# VPAC0_CP_INTD_CFG_INTD_CFG register map
Vendor: Texas Instruments
Peripheral module from a debugger description file (folder J7ES).
Registers are 32-bit, access not given, reset values left out (the file's numbers can be read two ways) unless marked. A register's access mark holds for its fields unless they carry their own. Offsets are as the file gives them; lines under a group give offsets from that group; [hi:lo] are bit positions; {n}, {i} and the like mark numbered series; 'fields as' and 'values as' point back to an identical list; <NAME> marks a mode.

## VPAC0_CP_INTD_CFG_INTD_CFG (part 1 of 2)
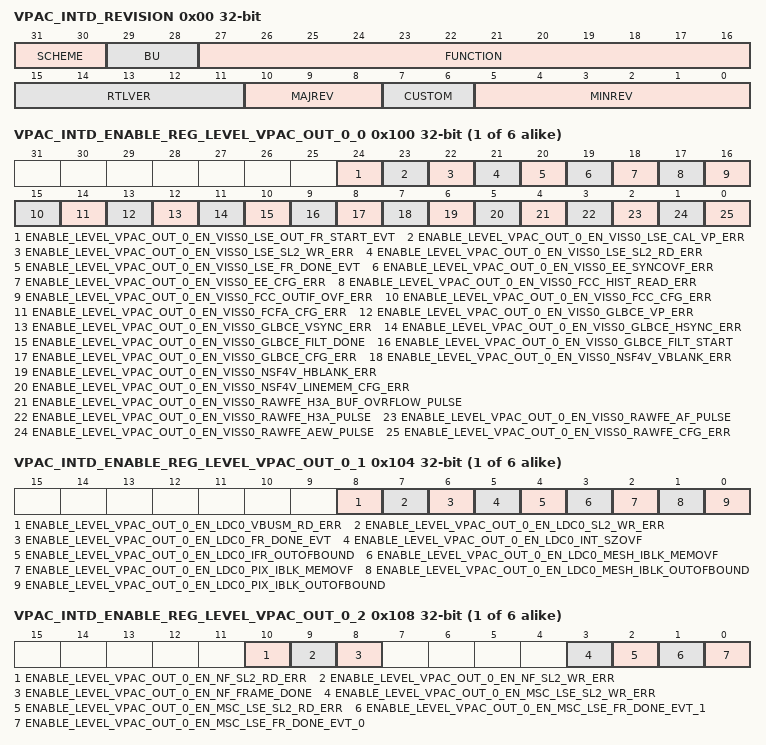
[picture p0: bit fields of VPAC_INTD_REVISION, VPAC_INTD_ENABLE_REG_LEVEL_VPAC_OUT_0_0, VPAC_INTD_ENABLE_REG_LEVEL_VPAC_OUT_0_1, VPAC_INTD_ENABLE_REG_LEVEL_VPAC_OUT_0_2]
0x00 VPAC_INTD_REVISION ro — Register
  [31:30] SCHEME
  [29:28] BU
  [27:16] FUNCTION — Module ID
  [15:11] RTLVER — RTL revisions
  [10:8] MAJREV — Major
  [7:6] CUSTOM
  [5:0] MINREV — Minor
0x10 VPAC_INTD_EOI_REG rw — End of Interrupt Register The EOI register is used to re-trigger the pulse interrupt signal to ensure that any nested interrupt events are serviced. The software interrupt handler must write to the EOI register at the end of the current interrupt processing routine, so that new events can re-trigger the pulse interrupt signal again. For level interrupt signals the EOI register is not functional and must not be used.
  [7:0] EOI_VECTOR — End of Interrupt Vector
0x14 VPAC_INTD_INTR_VECTOR_REG ro — Interrupt Vector Register
  [31:0] INTR_VECTOR
{0x100+0x20*i} VPAC_INTD_ENABLE_REG_LEVEL_VPAC_OUT_{i}_0 (i=0..5) — Enable Register {8i}
  [24] ENABLE_LEVEL_VPAC_OUT_{i}_EN_VISS0_LSE_OUT_FR_START_EVT — Enable Set for level_vpac_out_{i}_en_viss0_lse_out_fr_start_evt (access RW1S)
  [23] ENABLE_LEVEL_VPAC_OUT_{i}_EN_VISS0_LSE_CAL_VP_ERR — Enable Set for level_vpac_out_{i}_en_viss0_lse_cal_vp_err (access RW1S)
  [22] ENABLE_LEVEL_VPAC_OUT_{i}_EN_VISS0_LSE_SL2_WR_ERR — Enable Set for level_vpac_out_{i}_en_viss0_lse_sl2_wr_err (access RW1S)
  [21] ENABLE_LEVEL_VPAC_OUT_{i}_EN_VISS0_LSE_SL2_RD_ERR — Enable Set for level_vpac_out_{i}_en_viss0_lse_sl2_rd_err (access RW1S)
  [20] ENABLE_LEVEL_VPAC_OUT_{i}_EN_VISS0_LSE_FR_DONE_EVT — Enable Set for level_vpac_out_{i}_en_viss0_lse_fr_done_evt (access RW1S)
  [19] ENABLE_LEVEL_VPAC_OUT_{i}_EN_VISS0_EE_SYNCOVF_ERR — Enable Set for level_vpac_out_{i}_en_viss0_ee_syncovf_err (access RW1S)
  [18] ENABLE_LEVEL_VPAC_OUT_{i}_EN_VISS0_EE_CFG_ERR — Enable Set for level_vpac_out_{i}_en_viss0_ee_cfg_err (access RW1S)
  [17] ENABLE_LEVEL_VPAC_OUT_{i}_EN_VISS0_FCC_HIST_READ_ERR — Enable Set for level_vpac_out_{i}_en_viss0_fcc_hist_read_err (access RW1S)
  [16] ENABLE_LEVEL_VPAC_OUT_{i}_EN_VISS0_FCC_OUTIF_OVF_ERR — Enable Set for level_vpac_out_{i}_en_viss0_fcc_outif_ovf_err (access RW1S)
  [15] ENABLE_LEVEL_VPAC_OUT_{i}_EN_VISS0_FCC_CFG_ERR — Enable Set for level_vpac_out_{i}_en_viss0_fcc_cfg_err (access RW1S)
  [14] ENABLE_LEVEL_VPAC_OUT_{i}_EN_VISS0_FCFA_CFG_ERR — Enable Set for level_vpac_out_{i}_en_viss0_fcfa_cfg_err (access RW1S)
  [13] ENABLE_LEVEL_VPAC_OUT_{i}_EN_VISS0_GLBCE_VP_ERR — Enable Set for level_vpac_out_{i}_en_viss0_glbce_vp_err (access RW1S)
  [12] ENABLE_LEVEL_VPAC_OUT_{i}_EN_VISS0_GLBCE_VSYNC_ERR — Enable Set for level_vpac_out_{i}_en_viss0_glbce_vsync_err (access RW1S)
  [11] ENABLE_LEVEL_VPAC_OUT_{i}_EN_VISS0_GLBCE_HSYNC_ERR — Enable Set for level_vpac_out_{i}_en_viss0_glbce_hsync_err (access RW1S)
  [10] ENABLE_LEVEL_VPAC_OUT_{i}_EN_VISS0_GLBCE_FILT_DONE — Enable Set for level_vpac_out_{i}_en_viss0_glbce_filt_done (access RW1S)
  [9] ENABLE_LEVEL_VPAC_OUT_{i}_EN_VISS0_GLBCE_FILT_START — Enable Set for level_vpac_out_{i}_en_viss0_glbce_filt_start (access RW1S)
  [8] ENABLE_LEVEL_VPAC_OUT_{i}_EN_VISS0_GLBCE_CFG_ERR — Enable Set for level_vpac_out_{i}_en_viss0_glbce_cfg_err (access RW1S)
  [7] ENABLE_LEVEL_VPAC_OUT_{i}_EN_VISS0_NSF4V_VBLANK_ERR — Enable Set for level_vpac_out_{i}_en_viss0_nsf4v_vblank_err (access RW1S)
  [6] ENABLE_LEVEL_VPAC_OUT_{i}_EN_VISS0_NSF4V_HBLANK_ERR — Enable Set for level_vpac_out_{i}_en_viss0_nsf4v_hblank_err (access RW1S)
  [5] ENABLE_LEVEL_VPAC_OUT_{i}_EN_VISS0_NSF4V_LINEMEM_CFG_ERR — Enable Set for level_vpac_out_{i}_en_viss0_nsf4v_linemem_cfg_err (access RW1S)
  [4] ENABLE_LEVEL_VPAC_OUT_{i}_EN_VISS0_RAWFE_H3A_BUF_OVRFLOW_PULSE — Enable Set for level_vpac_out_{i}_en_viss0_rawfe_h3a_buf_ovrflow_pulse (access RW1S)
  [3] ENABLE_LEVEL_VPAC_OUT_{i}_EN_VISS0_RAWFE_H3A_PULSE — Enable Set for level_vpac_out_{i}_en_viss0_rawfe_h3a_pulse (access RW1S)
  [2] ENABLE_LEVEL_VPAC_OUT_{i}_EN_VISS0_RAWFE_AF_PULSE — Enable Set for level_vpac_out_{i}_en_viss0_rawfe_af_pulse (access RW1S)
  [1] ENABLE_LEVEL_VPAC_OUT_{i}_EN_VISS0_RAWFE_AEW_PULSE — Enable Set for level_vpac_out_{i}_en_viss0_rawfe_aew_pulse (access RW1S)
  [0] ENABLE_LEVEL_VPAC_OUT_{i}_EN_VISS0_RAWFE_CFG_ERR — Enable Set for level_vpac_out_{i}_en_viss0_rawfe_cfg_err (access RW1S)
{0x104+0x20*i} VPAC_INTD_ENABLE_REG_LEVEL_VPAC_OUT_{i}_1 (i=0..5) — Enable Register {8i+1}
  [8] ENABLE_LEVEL_VPAC_OUT_{i}_EN_LDC0_VBUSM_RD_ERR — Enable Set for level_vpac_out_{i}_en_ldc0_vbusm_rd_err (access RW1S)
  [7] ENABLE_LEVEL_VPAC_OUT_{i}_EN_LDC0_SL2_WR_ERR — Enable Set for level_vpac_out_{i}_en_ldc0_sl2_wr_err (access RW1S)
  [6] ENABLE_LEVEL_VPAC_OUT_{i}_EN_LDC0_FR_DONE_EVT — Enable Set for level_vpac_out_{i}_en_ldc0_fr_done_evt (access RW1S)
  [5] ENABLE_LEVEL_VPAC_OUT_{i}_EN_LDC0_INT_SZOVF — Enable Set for level_vpac_out_{i}_en_ldc0_int_szovf (access RW1S)
  [4] ENABLE_LEVEL_VPAC_OUT_{i}_EN_LDC0_IFR_OUTOFBOUND — Enable Set for level_vpac_out_{i}_en_ldc0_ifr_outofbound (access RW1S)
  [3] ENABLE_LEVEL_VPAC_OUT_{i}_EN_LDC0_MESH_IBLK_MEMOVF — Enable Set for level_vpac_out_{i}_en_ldc0_mesh_iblk_memovf (access RW1S)
  [2] ENABLE_LEVEL_VPAC_OUT_{i}_EN_LDC0_PIX_IBLK_MEMOVF — Enable Set for level_vpac_out_{i}_en_ldc0_pix_iblk_memovf (access RW1S)
  [1] ENABLE_LEVEL_VPAC_OUT_{i}_EN_LDC0_MESH_IBLK_OUTOFBOUND — Enable Set for level_vpac_out_{i}_en_ldc0_mesh_iblk_outofbound (access RW1S)
  [0] ENABLE_LEVEL_VPAC_OUT_{i}_EN_LDC0_PIX_IBLK_OUTOFBOUND — Enable Set for level_vpac_out_{i}_en_ldc0_pix_iblk_outofbound (access RW1S)
{0x108+0x20*i} VPAC_INTD_ENABLE_REG_LEVEL_VPAC_OUT_{i}_2 (i=0..5) — Enable Register {8i+2}
  [10] ENABLE_LEVEL_VPAC_OUT_{i}_EN_NF_SL2_RD_ERR — Enable Set for level_vpac_out_{i}_en_nf_sl2_rd_err (access RW1S)
  [9] ENABLE_LEVEL_VPAC_OUT_{i}_EN_NF_SL2_WR_ERR — Enable Set for level_vpac_out_{i}_en_nf_sl2_wr_err (access RW1S)
  [8] ENABLE_LEVEL_VPAC_OUT_{i}_EN_NF_FRAME_DONE — Enable Set for level_vpac_out_{i}_en_nf_frame_done (access RW1S)
  [3] ENABLE_LEVEL_VPAC_OUT_{i}_EN_MSC_LSE_SL2_WR_ERR — Enable Set for level_vpac_out_{i}_en_msc_lse_sl2_wr_err (access RW1S)
  [2] ENABLE_LEVEL_VPAC_OUT_{i}_EN_MSC_LSE_SL2_RD_ERR — Enable Set for level_vpac_out_{i}_en_msc_lse_sl2_rd_err (access RW1S)
  [1] ENABLE_LEVEL_VPAC_OUT_{i}_EN_MSC_LSE_FR_DONE_EVT_1 — Enable Set for level_vpac_out_{i}_en_msc_lse_fr_done_evt_1 (access RW1S)
  [0] ENABLE_LEVEL_VPAC_OUT_{i}_EN_MSC_LSE_FR_DONE_EVT_0 — Enable Set for level_vpac_out_{i}_en_msc_lse_fr_done_evt_0 (access RW1S)
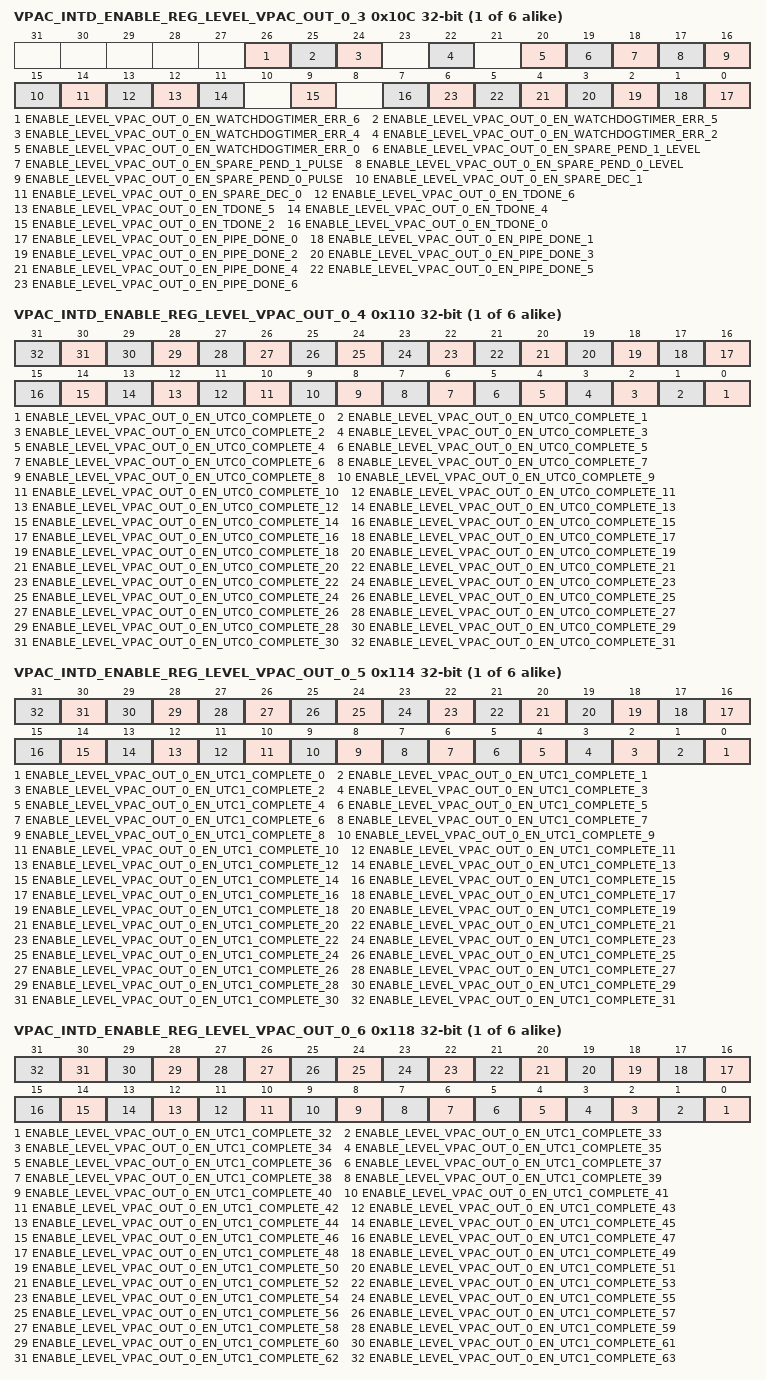
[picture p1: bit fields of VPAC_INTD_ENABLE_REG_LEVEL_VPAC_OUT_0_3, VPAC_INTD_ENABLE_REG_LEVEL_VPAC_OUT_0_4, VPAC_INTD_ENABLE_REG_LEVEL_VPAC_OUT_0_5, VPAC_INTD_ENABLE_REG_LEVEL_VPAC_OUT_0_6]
{0x10C+0x20*i} VPAC_INTD_ENABLE_REG_LEVEL_VPAC_OUT_{i}_3 (i=0..5) — Enable Register {8i+3}
  [26] ENABLE_LEVEL_VPAC_OUT_{i}_EN_WATCHDOGTIMER_ERR_6 — Enable Set for level_vpac_out_{i}_en_watchdogtimer_err_6 (access RW1S)
  [25] ENABLE_LEVEL_VPAC_OUT_{i}_EN_WATCHDOGTIMER_ERR_5 — Enable Set for level_vpac_out_{i}_en_watchdogtimer_err_5 (access RW1S)
  [24] ENABLE_LEVEL_VPAC_OUT_{i}_EN_WATCHDOGTIMER_ERR_4 — Enable Set for level_vpac_out_{i}_en_watchdogtimer_err_4 (access RW1S)
  [22] ENABLE_LEVEL_VPAC_OUT_{i}_EN_WATCHDOGTIMER_ERR_2 — Enable Set for level_vpac_out_{i}_en_watchdogtimer_err_2 (access RW1S)
  [20] ENABLE_LEVEL_VPAC_OUT_{i}_EN_WATCHDOGTIMER_ERR_0 — Enable Set for level_vpac_out_{i}_en_watchdogtimer_err_0 (access RW1S)
  [19] ENABLE_LEVEL_VPAC_OUT_{i}_EN_SPARE_PEND_1_LEVEL — Enable Set for level_vpac_out_{i}_en_spare_pend_1_level (access RW1S)
  [18] ENABLE_LEVEL_VPAC_OUT_{i}_EN_SPARE_PEND_1_PULSE — Enable Set for level_vpac_out_{i}_en_spare_pend_1_pulse (access RW1S)
  [17] ENABLE_LEVEL_VPAC_OUT_{i}_EN_SPARE_PEND_0_LEVEL — Enable Set for level_vpac_out_{i}_en_spare_pend_0_level (access RW1S)
  [16] ENABLE_LEVEL_VPAC_OUT_{i}_EN_SPARE_PEND_0_PULSE — Enable Set for level_vpac_out_{i}_en_spare_pend_0_pulse (access RW1S)
  [15] ENABLE_LEVEL_VPAC_OUT_{i}_EN_SPARE_DEC_1 — Enable Set for level_vpac_out_{i}_en_spare_dec_1 (access RW1S)
  [14] ENABLE_LEVEL_VPAC_OUT_{i}_EN_SPARE_DEC_0 — Enable Set for level_vpac_out_{i}_en_spare_dec_0 (access RW1S)
  [13] ENABLE_LEVEL_VPAC_OUT_{i}_EN_TDONE_6 — Enable Set for level_vpac_out_{i}_en_tdone_6 (access RW1S)
  [12] ENABLE_LEVEL_VPAC_OUT_{i}_EN_TDONE_5 — Enable Set for level_vpac_out_{i}_en_tdone_5 (access RW1S)
  [11] ENABLE_LEVEL_VPAC_OUT_{i}_EN_TDONE_4 — Enable Set for level_vpac_out_{i}_en_tdone_4 (access RW1S)
  [9] ENABLE_LEVEL_VPAC_OUT_{i}_EN_TDONE_2 — Enable Set for level_vpac_out_{i}_en_tdone_2 (access RW1S)
  [7] ENABLE_LEVEL_VPAC_OUT_{i}_EN_TDONE_0 — Enable Set for level_vpac_out_{i}_en_tdone_0 (access RW1S)
  [n] ENABLE_LEVEL_VPAC_OUT_{i}_EN_PIPE_DONE_{n} (n=0..6) — Enable Set for level_vpac_out_{i}_en_pipe_done_{n} (access RW1S)
{0x110+0x20*i} VPAC_INTD_ENABLE_REG_LEVEL_VPAC_OUT_{i}_4 (i=0..5) — Enable Register {8i+4}
  [n] ENABLE_LEVEL_VPAC_OUT_{i}_EN_UTC0_COMPLETE_{n} (n=0..31) — Enable Set for level_vpac_out_{i}_en_utc0_complete_{n} (access RW1S)
{0x114+0x20*i} VPAC_INTD_ENABLE_REG_LEVEL_VPAC_OUT_{i}_5 (i=0..5) — Enable Register {8i+5}
  [n] ENABLE_LEVEL_VPAC_OUT_{i}_EN_UTC1_COMPLETE_{n} (n=0..31) — Enable Set for level_vpac_out_{i}_en_utc1_complete_{n} (access RW1S)
{0x118+0x20*i} VPAC_INTD_ENABLE_REG_LEVEL_VPAC_OUT_{i}_6 (i=0..5) — Enable Register {8i+6}
  [n-32] ENABLE_LEVEL_VPAC_OUT_{i}_EN_UTC1_COMPLETE_{n} (n=32..63) — Enable Set for level_vpac_out_{i}_en_utc1_complete_{n} (access RW1S)
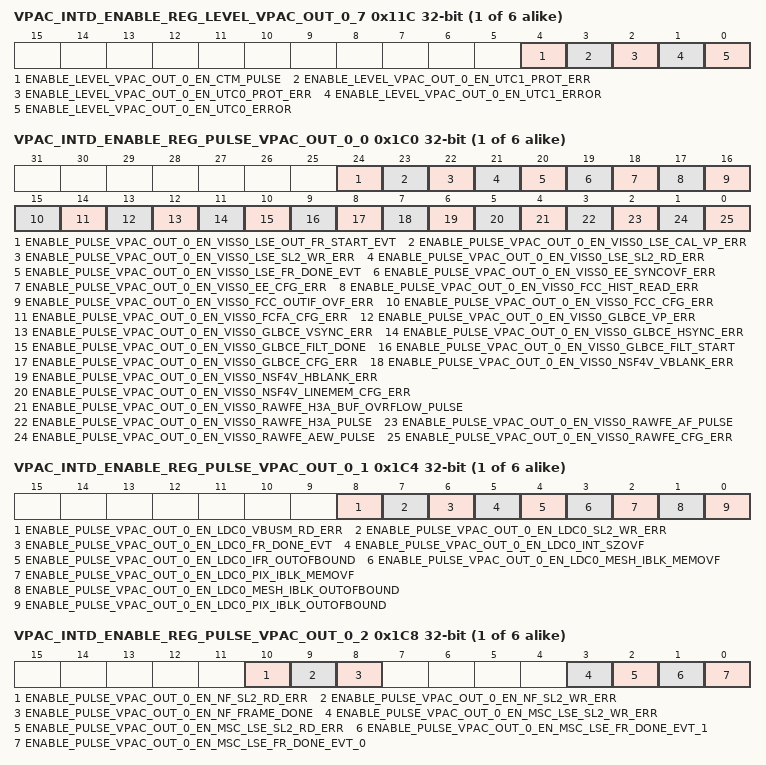
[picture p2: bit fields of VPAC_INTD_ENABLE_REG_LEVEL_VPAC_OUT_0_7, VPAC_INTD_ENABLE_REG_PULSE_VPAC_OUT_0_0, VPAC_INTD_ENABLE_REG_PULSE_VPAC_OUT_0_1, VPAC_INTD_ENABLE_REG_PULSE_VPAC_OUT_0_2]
{0x11C+0x20*i} VPAC_INTD_ENABLE_REG_LEVEL_VPAC_OUT_{i}_7 (i=0..5) — Enable Register {8i+7}
  [4] ENABLE_LEVEL_VPAC_OUT_{i}_EN_CTM_PULSE — Enable Set for level_vpac_out_{i}_en_ctm_pulse (access RW1S)
  [3] ENABLE_LEVEL_VPAC_OUT_{i}_EN_UTC1_PROT_ERR — Enable Set for level_vpac_out_{i}_en_utc1_prot_err (access RW1S)
  [2] ENABLE_LEVEL_VPAC_OUT_{i}_EN_UTC0_PROT_ERR — Enable Set for level_vpac_out_{i}_en_utc0_prot_err (access RW1S)
  [1] ENABLE_LEVEL_VPAC_OUT_{i}_EN_UTC1_ERROR — Enable Set for level_vpac_out_{i}_en_utc1_error (access RW1S)
  [0] ENABLE_LEVEL_VPAC_OUT_{i}_EN_UTC0_ERROR — Enable Set for level_vpac_out_{i}_en_utc0_error (access RW1S)
{0x1C0+0x20*i} VPAC_INTD_ENABLE_REG_PULSE_VPAC_OUT_{i}_0 (i=0..5) — Enable Register {8i+48}
  [24] ENABLE_PULSE_VPAC_OUT_{i}_EN_VISS0_LSE_OUT_FR_START_EVT — Enable Set for pulse_vpac_out_{i}_en_viss0_lse_out_fr_start_evt (access RW1S)
  [23] ENABLE_PULSE_VPAC_OUT_{i}_EN_VISS0_LSE_CAL_VP_ERR — Enable Set for pulse_vpac_out_{i}_en_viss0_lse_cal_vp_err (access RW1S)
  [22] ENABLE_PULSE_VPAC_OUT_{i}_EN_VISS0_LSE_SL2_WR_ERR — Enable Set for pulse_vpac_out_{i}_en_viss0_lse_sl2_wr_err (access RW1S)
  [21] ENABLE_PULSE_VPAC_OUT_{i}_EN_VISS0_LSE_SL2_RD_ERR — Enable Set for pulse_vpac_out_{i}_en_viss0_lse_sl2_rd_err (access RW1S)
  [20] ENABLE_PULSE_VPAC_OUT_{i}_EN_VISS0_LSE_FR_DONE_EVT — Enable Set for pulse_vpac_out_{i}_en_viss0_lse_fr_done_evt (access RW1S)
  [19] ENABLE_PULSE_VPAC_OUT_{i}_EN_VISS0_EE_SYNCOVF_ERR — Enable Set for pulse_vpac_out_{i}_en_viss0_ee_syncovf_err (access RW1S)
  [18] ENABLE_PULSE_VPAC_OUT_{i}_EN_VISS0_EE_CFG_ERR — Enable Set for pulse_vpac_out_{i}_en_viss0_ee_cfg_err (access RW1S)
  [17] ENABLE_PULSE_VPAC_OUT_{i}_EN_VISS0_FCC_HIST_READ_ERR — Enable Set for pulse_vpac_out_{i}_en_viss0_fcc_hist_read_err (access RW1S)
  [16] ENABLE_PULSE_VPAC_OUT_{i}_EN_VISS0_FCC_OUTIF_OVF_ERR — Enable Set for pulse_vpac_out_{i}_en_viss0_fcc_outif_ovf_err (access RW1S)
  [15] ENABLE_PULSE_VPAC_OUT_{i}_EN_VISS0_FCC_CFG_ERR — Enable Set for pulse_vpac_out_{i}_en_viss0_fcc_cfg_err (access RW1S)
  [14] ENABLE_PULSE_VPAC_OUT_{i}_EN_VISS0_FCFA_CFG_ERR — Enable Set for pulse_vpac_out_{i}_en_viss0_fcfa_cfg_err (access RW1S)
  [13] ENABLE_PULSE_VPAC_OUT_{i}_EN_VISS0_GLBCE_VP_ERR — Enable Set for pulse_vpac_out_{i}_en_viss0_glbce_vp_err (access RW1S)
  [12] ENABLE_PULSE_VPAC_OUT_{i}_EN_VISS0_GLBCE_VSYNC_ERR — Enable Set for pulse_vpac_out_{i}_en_viss0_glbce_vsync_err (access RW1S)
  [11] ENABLE_PULSE_VPAC_OUT_{i}_EN_VISS0_GLBCE_HSYNC_ERR — Enable Set for pulse_vpac_out_{i}_en_viss0_glbce_hsync_err (access RW1S)
  [10] ENABLE_PULSE_VPAC_OUT_{i}_EN_VISS0_GLBCE_FILT_DONE — Enable Set for pulse_vpac_out_{i}_en_viss0_glbce_filt_done (access RW1S)
  [9] ENABLE_PULSE_VPAC_OUT_{i}_EN_VISS0_GLBCE_FILT_START — Enable Set for pulse_vpac_out_{i}_en_viss0_glbce_filt_start (access RW1S)
  [8] ENABLE_PULSE_VPAC_OUT_{i}_EN_VISS0_GLBCE_CFG_ERR — Enable Set for pulse_vpac_out_{i}_en_viss0_glbce_cfg_err (access RW1S)
  [7] ENABLE_PULSE_VPAC_OUT_{i}_EN_VISS0_NSF4V_VBLANK_ERR — Enable Set for pulse_vpac_out_{i}_en_viss0_nsf4v_vblank_err (access RW1S)
  [6] ENABLE_PULSE_VPAC_OUT_{i}_EN_VISS0_NSF4V_HBLANK_ERR — Enable Set for pulse_vpac_out_{i}_en_viss0_nsf4v_hblank_err (access RW1S)
  [5] ENABLE_PULSE_VPAC_OUT_{i}_EN_VISS0_NSF4V_LINEMEM_CFG_ERR — Enable Set for pulse_vpac_out_{i}_en_viss0_nsf4v_linemem_cfg_err (access RW1S)
  [4] ENABLE_PULSE_VPAC_OUT_{i}_EN_VISS0_RAWFE_H3A_BUF_OVRFLOW_PULSE — Enable Set for pulse_vpac_out_{i}_en_viss0_rawfe_h3a_buf_ovrflow_pulse (access RW1S)
  [3] ENABLE_PULSE_VPAC_OUT_{i}_EN_VISS0_RAWFE_H3A_PULSE — Enable Set for pulse_vpac_out_{i}_en_viss0_rawfe_h3a_pulse (access RW1S)
  [2] ENABLE_PULSE_VPAC_OUT_{i}_EN_VISS0_RAWFE_AF_PULSE — Enable Set for pulse_vpac_out_{i}_en_viss0_rawfe_af_pulse (access RW1S)
  [1] ENABLE_PULSE_VPAC_OUT_{i}_EN_VISS0_RAWFE_AEW_PULSE — Enable Set for pulse_vpac_out_{i}_en_viss0_rawfe_aew_pulse (access RW1S)
  [0] ENABLE_PULSE_VPAC_OUT_{i}_EN_VISS0_RAWFE_CFG_ERR — Enable Set for pulse_vpac_out_{i}_en_viss0_rawfe_cfg_err (access RW1S)
{0x1C4+0x20*i} VPAC_INTD_ENABLE_REG_PULSE_VPAC_OUT_{i}_1 (i=0..5) — Enable Register {8i+49}
  [8] ENABLE_PULSE_VPAC_OUT_{i}_EN_LDC0_VBUSM_RD_ERR — Enable Set for pulse_vpac_out_{i}_en_ldc0_vbusm_rd_err (access RW1S)
  [7] ENABLE_PULSE_VPAC_OUT_{i}_EN_LDC0_SL2_WR_ERR — Enable Set for pulse_vpac_out_{i}_en_ldc0_sl2_wr_err (access RW1S)
  [6] ENABLE_PULSE_VPAC_OUT_{i}_EN_LDC0_FR_DONE_EVT — Enable Set for pulse_vpac_out_{i}_en_ldc0_fr_done_evt (access RW1S)
  [5] ENABLE_PULSE_VPAC_OUT_{i}_EN_LDC0_INT_SZOVF — Enable Set for pulse_vpac_out_{i}_en_ldc0_int_szovf (access RW1S)
  [4] ENABLE_PULSE_VPAC_OUT_{i}_EN_LDC0_IFR_OUTOFBOUND — Enable Set for pulse_vpac_out_{i}_en_ldc0_ifr_outofbound (access RW1S)
  [3] ENABLE_PULSE_VPAC_OUT_{i}_EN_LDC0_MESH_IBLK_MEMOVF — Enable Set for pulse_vpac_out_{i}_en_ldc0_mesh_iblk_memovf (access RW1S)
  [2] ENABLE_PULSE_VPAC_OUT_{i}_EN_LDC0_PIX_IBLK_MEMOVF — Enable Set for pulse_vpac_out_{i}_en_ldc0_pix_iblk_memovf (access RW1S)
  [1] ENABLE_PULSE_VPAC_OUT_{i}_EN_LDC0_MESH_IBLK_OUTOFBOUND — Enable Set for pulse_vpac_out_{i}_en_ldc0_mesh_iblk_outofbound (access RW1S)
  [0] ENABLE_PULSE_VPAC_OUT_{i}_EN_LDC0_PIX_IBLK_OUTOFBOUND — Enable Set for pulse_vpac_out_{i}_en_ldc0_pix_iblk_outofbound (access RW1S)
{0x1C8+0x20*i} VPAC_INTD_ENABLE_REG_PULSE_VPAC_OUT_{i}_2 (i=0..5) — Enable Register {8i+50}
  [10] ENABLE_PULSE_VPAC_OUT_{i}_EN_NF_SL2_RD_ERR — Enable Set for pulse_vpac_out_{i}_en_nf_sl2_rd_err (access RW1S)
  [9] ENABLE_PULSE_VPAC_OUT_{i}_EN_NF_SL2_WR_ERR — Enable Set for pulse_vpac_out_{i}_en_nf_sl2_wr_err (access RW1S)
  [8] ENABLE_PULSE_VPAC_OUT_{i}_EN_NF_FRAME_DONE — Enable Set for pulse_vpac_out_{i}_en_nf_frame_done (access RW1S)
  [3] ENABLE_PULSE_VPAC_OUT_{i}_EN_MSC_LSE_SL2_WR_ERR — Enable Set for pulse_vpac_out_{i}_en_msc_lse_sl2_wr_err (access RW1S)
  [2] ENABLE_PULSE_VPAC_OUT_{i}_EN_MSC_LSE_SL2_RD_ERR — Enable Set for pulse_vpac_out_{i}_en_msc_lse_sl2_rd_err (access RW1S)
  [1] ENABLE_PULSE_VPAC_OUT_{i}_EN_MSC_LSE_FR_DONE_EVT_1 — Enable Set for pulse_vpac_out_{i}_en_msc_lse_fr_done_evt_1 (access RW1S)
  [0] ENABLE_PULSE_VPAC_OUT_{i}_EN_MSC_LSE_FR_DONE_EVT_0 — Enable Set for pulse_vpac_out_{i}_en_msc_lse_fr_done_evt_0 (access RW1S)
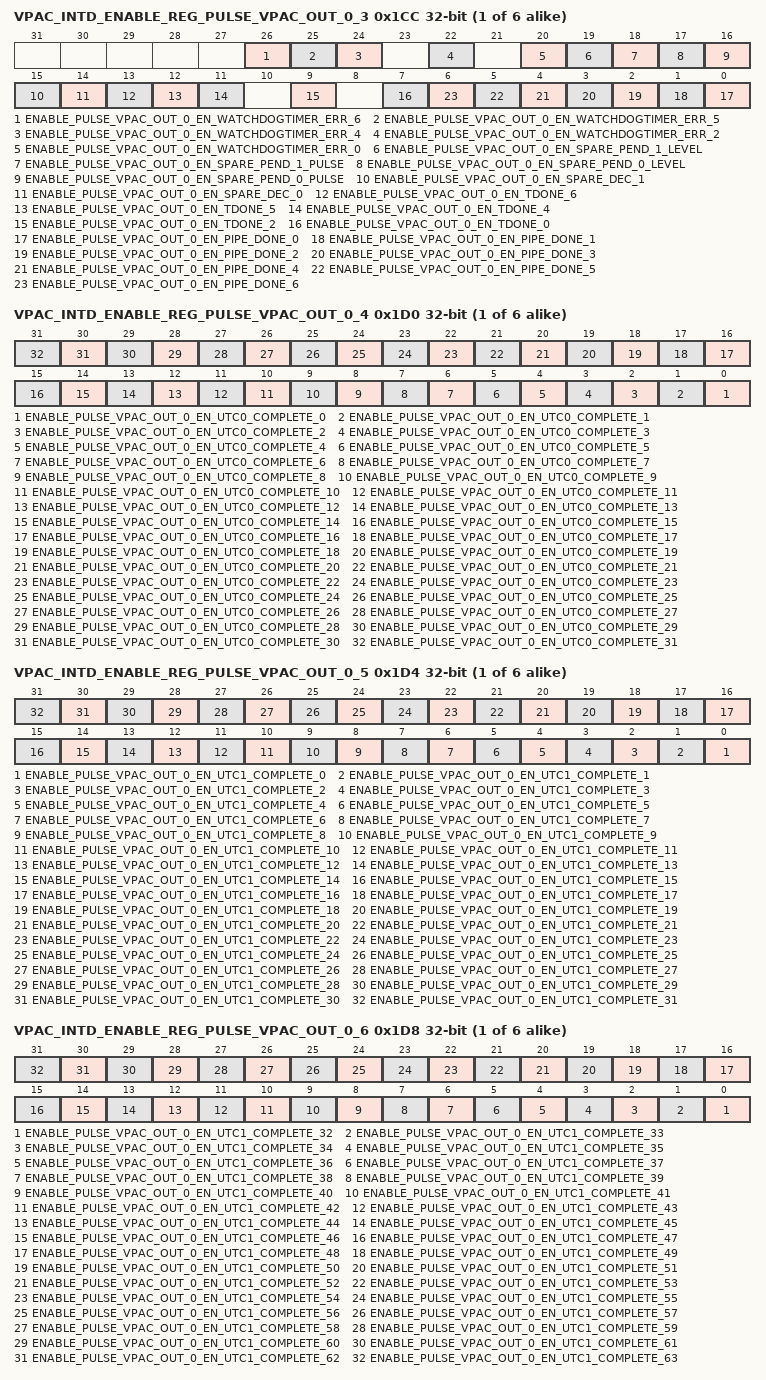
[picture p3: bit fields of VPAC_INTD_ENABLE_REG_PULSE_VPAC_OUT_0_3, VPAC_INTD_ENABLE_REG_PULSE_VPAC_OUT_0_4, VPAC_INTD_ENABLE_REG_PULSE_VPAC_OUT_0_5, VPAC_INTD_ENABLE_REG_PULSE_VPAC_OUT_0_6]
{0x1CC+0x20*i} VPAC_INTD_ENABLE_REG_PULSE_VPAC_OUT_{i}_3 (i=0..5) — Enable Register {8i+51}
  [26] ENABLE_PULSE_VPAC_OUT_{i}_EN_WATCHDOGTIMER_ERR_6 — Enable Set for pulse_vpac_out_{i}_en_watchdogtimer_err_6 (access RW1S)
  [25] ENABLE_PULSE_VPAC_OUT_{i}_EN_WATCHDOGTIMER_ERR_5 — Enable Set for pulse_vpac_out_{i}_en_watchdogtimer_err_5 (access RW1S)
  [24] ENABLE_PULSE_VPAC_OUT_{i}_EN_WATCHDOGTIMER_ERR_4 — Enable Set for pulse_vpac_out_{i}_en_watchdogtimer_err_4 (access RW1S)
  [22] ENABLE_PULSE_VPAC_OUT_{i}_EN_WATCHDOGTIMER_ERR_2 — Enable Set for pulse_vpac_out_{i}_en_watchdogtimer_err_2 (access RW1S)
  [20] ENABLE_PULSE_VPAC_OUT_{i}_EN_WATCHDOGTIMER_ERR_0 — Enable Set for pulse_vpac_out_{i}_en_watchdogtimer_err_0 (access RW1S)
  [19] ENABLE_PULSE_VPAC_OUT_{i}_EN_SPARE_PEND_1_LEVEL — Enable Set for pulse_vpac_out_{i}_en_spare_pend_1_level (access RW1S)
  [18] ENABLE_PULSE_VPAC_OUT_{i}_EN_SPARE_PEND_1_PULSE — Enable Set for pulse_vpac_out_{i}_en_spare_pend_1_pulse (access RW1S)
  [17] ENABLE_PULSE_VPAC_OUT_{i}_EN_SPARE_PEND_0_LEVEL — Enable Set for pulse_vpac_out_{i}_en_spare_pend_0_level (access RW1S)
  [16] ENABLE_PULSE_VPAC_OUT_{i}_EN_SPARE_PEND_0_PULSE — Enable Set for pulse_vpac_out_{i}_en_spare_pend_0_pulse (access RW1S)
  [15] ENABLE_PULSE_VPAC_OUT_{i}_EN_SPARE_DEC_1 — Enable Set for pulse_vpac_out_{i}_en_spare_dec_1 (access RW1S)
  [14] ENABLE_PULSE_VPAC_OUT_{i}_EN_SPARE_DEC_0 — Enable Set for pulse_vpac_out_{i}_en_spare_dec_0 (access RW1S)
  [13] ENABLE_PULSE_VPAC_OUT_{i}_EN_TDONE_6 — Enable Set for pulse_vpac_out_{i}_en_tdone_6 (access RW1S)
  [12] ENABLE_PULSE_VPAC_OUT_{i}_EN_TDONE_5 — Enable Set for pulse_vpac_out_{i}_en_tdone_5 (access RW1S)
  [11] ENABLE_PULSE_VPAC_OUT_{i}_EN_TDONE_4 — Enable Set for pulse_vpac_out_{i}_en_tdone_4 (access RW1S)
  [9] ENABLE_PULSE_VPAC_OUT_{i}_EN_TDONE_2 — Enable Set for pulse_vpac_out_{i}_en_tdone_2 (access RW1S)
  [7] ENABLE_PULSE_VPAC_OUT_{i}_EN_TDONE_0 — Enable Set for pulse_vpac_out_{i}_en_tdone_0 (access RW1S)
  [n] ENABLE_PULSE_VPAC_OUT_{i}_EN_PIPE_DONE_{n} (n=0..6) — Enable Set for pulse_vpac_out_{i}_en_pipe_done_{n} (access RW1S)
{0x1D0+0x20*i} VPAC_INTD_ENABLE_REG_PULSE_VPAC_OUT_{i}_4 (i=0..5) — Enable Register {8i+52}
  [n] ENABLE_PULSE_VPAC_OUT_{i}_EN_UTC0_COMPLETE_{n} (n=0..31) — Enable Set for pulse_vpac_out_{i}_en_utc0_complete_{n} (access RW1S)
{0x1D4+0x20*i} VPAC_INTD_ENABLE_REG_PULSE_VPAC_OUT_{i}_5 (i=0..5) — Enable Register {8i+53}
  [n] ENABLE_PULSE_VPAC_OUT_{i}_EN_UTC1_COMPLETE_{n} (n=0..31) — Enable Set for pulse_vpac_out_{i}_en_utc1_complete_{n} (access RW1S)
{0x1D8+0x20*i} VPAC_INTD_ENABLE_REG_PULSE_VPAC_OUT_{i}_6 (i=0..5) — Enable Register {8i+54}
  [n-32] ENABLE_PULSE_VPAC_OUT_{i}_EN_UTC1_COMPLETE_{n} (n=32..63) — Enable Set for pulse_vpac_out_{i}_en_utc1_complete_{n} (access RW1S)
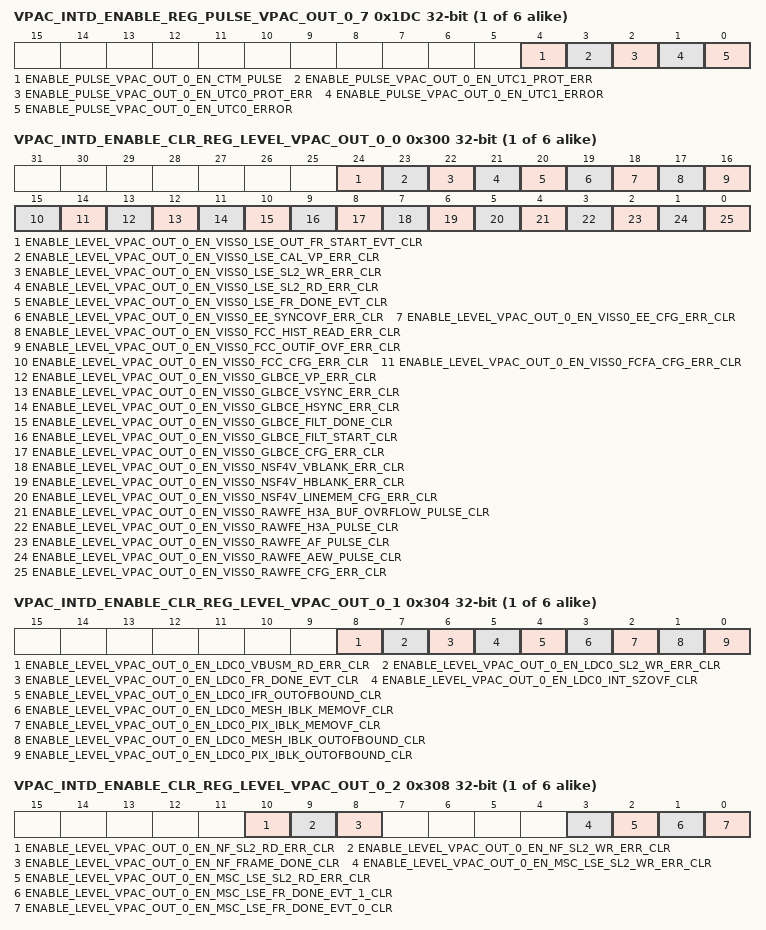
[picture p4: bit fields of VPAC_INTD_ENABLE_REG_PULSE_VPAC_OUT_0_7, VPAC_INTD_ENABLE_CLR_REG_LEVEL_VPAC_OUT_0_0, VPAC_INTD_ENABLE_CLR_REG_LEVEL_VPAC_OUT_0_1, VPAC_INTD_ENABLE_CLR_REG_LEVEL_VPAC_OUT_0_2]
{0x1DC+0x20*i} VPAC_INTD_ENABLE_REG_PULSE_VPAC_OUT_{i}_7 (i=0..5) — Enable Register {8i+55}
  [4] ENABLE_PULSE_VPAC_OUT_{i}_EN_CTM_PULSE — Enable Set for pulse_vpac_out_{i}_en_ctm_pulse (access RW1S)
  [3] ENABLE_PULSE_VPAC_OUT_{i}_EN_UTC1_PROT_ERR — Enable Set for pulse_vpac_out_{i}_en_utc1_prot_err (access RW1S)
  [2] ENABLE_PULSE_VPAC_OUT_{i}_EN_UTC0_PROT_ERR — Enable Set for pulse_vpac_out_{i}_en_utc0_prot_err (access RW1S)
  [1] ENABLE_PULSE_VPAC_OUT_{i}_EN_UTC1_ERROR — Enable Set for pulse_vpac_out_{i}_en_utc1_error (access RW1S)
  [0] ENABLE_PULSE_VPAC_OUT_{i}_EN_UTC0_ERROR — Enable Set for pulse_vpac_out_{i}_en_utc0_error (access RW1S)
{0x300+0x20*i} VPAC_INTD_ENABLE_CLR_REG_LEVEL_VPAC_OUT_{i}_0 (i=0..5) — Enable Clear Register {8i}
  [24] ENABLE_LEVEL_VPAC_OUT_{i}_EN_VISS0_LSE_OUT_FR_START_EVT_CLR — Enable Clear for level_vpac_out_{i}_en_viss0_lse_out_fr_start_evt (access RW1C)
  [23] ENABLE_LEVEL_VPAC_OUT_{i}_EN_VISS0_LSE_CAL_VP_ERR_CLR — Enable Clear for level_vpac_out_{i}_en_viss0_lse_cal_vp_err (access RW1C)
  [22] ENABLE_LEVEL_VPAC_OUT_{i}_EN_VISS0_LSE_SL2_WR_ERR_CLR — Enable Clear for level_vpac_out_{i}_en_viss0_lse_sl2_wr_err (access RW1C)
  [21] ENABLE_LEVEL_VPAC_OUT_{i}_EN_VISS0_LSE_SL2_RD_ERR_CLR — Enable Clear for level_vpac_out_{i}_en_viss0_lse_sl2_rd_err (access RW1C)
  [20] ENABLE_LEVEL_VPAC_OUT_{i}_EN_VISS0_LSE_FR_DONE_EVT_CLR — Enable Clear for level_vpac_out_{i}_en_viss0_lse_fr_done_evt (access RW1C)
  [19] ENABLE_LEVEL_VPAC_OUT_{i}_EN_VISS0_EE_SYNCOVF_ERR_CLR — Enable Clear for level_vpac_out_{i}_en_viss0_ee_syncovf_err (access RW1C)
  [18] ENABLE_LEVEL_VPAC_OUT_{i}_EN_VISS0_EE_CFG_ERR_CLR — Enable Clear for level_vpac_out_{i}_en_viss0_ee_cfg_err (access RW1C)
  [17] ENABLE_LEVEL_VPAC_OUT_{i}_EN_VISS0_FCC_HIST_READ_ERR_CLR — Enable Clear for level_vpac_out_{i}_en_viss0_fcc_hist_read_err (access RW1C)
  [16] ENABLE_LEVEL_VPAC_OUT_{i}_EN_VISS0_FCC_OUTIF_OVF_ERR_CLR — Enable Clear for level_vpac_out_{i}_en_viss0_fcc_outif_ovf_err (access RW1C)
  [15] ENABLE_LEVEL_VPAC_OUT_{i}_EN_VISS0_FCC_CFG_ERR_CLR — Enable Clear for level_vpac_out_{i}_en_viss0_fcc_cfg_err (access RW1C)
  [14] ENABLE_LEVEL_VPAC_OUT_{i}_EN_VISS0_FCFA_CFG_ERR_CLR — Enable Clear for level_vpac_out_{i}_en_viss0_fcfa_cfg_err (access RW1C)
  [13] ENABLE_LEVEL_VPAC_OUT_{i}_EN_VISS0_GLBCE_VP_ERR_CLR — Enable Clear for level_vpac_out_{i}_en_viss0_glbce_vp_err (access RW1C)
  [12] ENABLE_LEVEL_VPAC_OUT_{i}_EN_VISS0_GLBCE_VSYNC_ERR_CLR — Enable Clear for level_vpac_out_{i}_en_viss0_glbce_vsync_err (access RW1C)
  [11] ENABLE_LEVEL_VPAC_OUT_{i}_EN_VISS0_GLBCE_HSYNC_ERR_CLR — Enable Clear for level_vpac_out_{i}_en_viss0_glbce_hsync_err (access RW1C)
  [10] ENABLE_LEVEL_VPAC_OUT_{i}_EN_VISS0_GLBCE_FILT_DONE_CLR — Enable Clear for level_vpac_out_{i}_en_viss0_glbce_filt_done (access RW1C)
  [9] ENABLE_LEVEL_VPAC_OUT_{i}_EN_VISS0_GLBCE_FILT_START_CLR — Enable Clear for level_vpac_out_{i}_en_viss0_glbce_filt_start (access RW1C)
  [8] ENABLE_LEVEL_VPAC_OUT_{i}_EN_VISS0_GLBCE_CFG_ERR_CLR — Enable Clear for level_vpac_out_{i}_en_viss0_glbce_cfg_err (access RW1C)
  [7] ENABLE_LEVEL_VPAC_OUT_{i}_EN_VISS0_NSF4V_VBLANK_ERR_CLR — Enable Clear for level_vpac_out_{i}_en_viss0_nsf4v_vblank_err (access RW1C)
  [6] ENABLE_LEVEL_VPAC_OUT_{i}_EN_VISS0_NSF4V_HBLANK_ERR_CLR — Enable Clear for level_vpac_out_{i}_en_viss0_nsf4v_hblank_err (access RW1C)
  [5] ENABLE_LEVEL_VPAC_OUT_{i}_EN_VISS0_NSF4V_LINEMEM_CFG_ERR_CLR — Enable Clear for level_vpac_out_{i}_en_viss0_nsf4v_linemem_cfg_err (access RW1C)
  [4] ENABLE_LEVEL_VPAC_OUT_{i}_EN_VISS0_RAWFE_H3A_BUF_OVRFLOW_PULSE_CLR — Enable Clear for level_vpac_out_{i}_en_viss0_rawfe_h3a_buf_ovrflow_pulse (access RW1C)
  [3] ENABLE_LEVEL_VPAC_OUT_{i}_EN_VISS0_RAWFE_H3A_PULSE_CLR — Enable Clear for level_vpac_out_{i}_en_viss0_rawfe_h3a_pulse (access RW1C)
  [2] ENABLE_LEVEL_VPAC_OUT_{i}_EN_VISS0_RAWFE_AF_PULSE_CLR — Enable Clear for level_vpac_out_{i}_en_viss0_rawfe_af_pulse (access RW1C)
  [1] ENABLE_LEVEL_VPAC_OUT_{i}_EN_VISS0_RAWFE_AEW_PULSE_CLR — Enable Clear for level_vpac_out_{i}_en_viss0_rawfe_aew_pulse (access RW1C)
  [0] ENABLE_LEVEL_VPAC_OUT_{i}_EN_VISS0_RAWFE_CFG_ERR_CLR — Enable Clear for level_vpac_out_{i}_en_viss0_rawfe_cfg_err (access RW1C)
{0x304+0x20*i} VPAC_INTD_ENABLE_CLR_REG_LEVEL_VPAC_OUT_{i}_1 (i=0..5) — Enable Clear Register {8i+1}
  [8] ENABLE_LEVEL_VPAC_OUT_{i}_EN_LDC0_VBUSM_RD_ERR_CLR — Enable Clear for level_vpac_out_{i}_en_ldc0_vbusm_rd_err (access RW1C)
  [7] ENABLE_LEVEL_VPAC_OUT_{i}_EN_LDC0_SL2_WR_ERR_CLR — Enable Clear for level_vpac_out_{i}_en_ldc0_sl2_wr_err (access RW1C)
  [6] ENABLE_LEVEL_VPAC_OUT_{i}_EN_LDC0_FR_DONE_EVT_CLR — Enable Clear for level_vpac_out_{i}_en_ldc0_fr_done_evt (access RW1C)
  [5] ENABLE_LEVEL_VPAC_OUT_{i}_EN_LDC0_INT_SZOVF_CLR — Enable Clear for level_vpac_out_{i}_en_ldc0_int_szovf (access RW1C)
  [4] ENABLE_LEVEL_VPAC_OUT_{i}_EN_LDC0_IFR_OUTOFBOUND_CLR — Enable Clear for level_vpac_out_{i}_en_ldc0_ifr_outofbound (access RW1C)
  [3] ENABLE_LEVEL_VPAC_OUT_{i}_EN_LDC0_MESH_IBLK_MEMOVF_CLR — Enable Clear for level_vpac_out_{i}_en_ldc0_mesh_iblk_memovf (access RW1C)
  [2] ENABLE_LEVEL_VPAC_OUT_{i}_EN_LDC0_PIX_IBLK_MEMOVF_CLR — Enable Clear for level_vpac_out_{i}_en_ldc0_pix_iblk_memovf (access RW1C)
  [1] ENABLE_LEVEL_VPAC_OUT_{i}_EN_LDC0_MESH_IBLK_OUTOFBOUND_CLR — Enable Clear for level_vpac_out_{i}_en_ldc0_mesh_iblk_outofbound (access RW1C)
  [0] ENABLE_LEVEL_VPAC_OUT_{i}_EN_LDC0_PIX_IBLK_OUTOFBOUND_CLR — Enable Clear for level_vpac_out_{i}_en_ldc0_pix_iblk_outofbound (access RW1C)
{0x308+0x20*i} VPAC_INTD_ENABLE_CLR_REG_LEVEL_VPAC_OUT_{i}_2 (i=0..5) — Enable Clear Register {8i+2}
  [10] ENABLE_LEVEL_VPAC_OUT_{i}_EN_NF_SL2_RD_ERR_CLR — Enable Clear for level_vpac_out_{i}_en_nf_sl2_rd_err (access RW1C)
  [9] ENABLE_LEVEL_VPAC_OUT_{i}_EN_NF_SL2_WR_ERR_CLR — Enable Clear for level_vpac_out_{i}_en_nf_sl2_wr_err (access RW1C)
  [8] ENABLE_LEVEL_VPAC_OUT_{i}_EN_NF_FRAME_DONE_CLR — Enable Clear for level_vpac_out_{i}_en_nf_frame_done (access RW1C)
  [3] ENABLE_LEVEL_VPAC_OUT_{i}_EN_MSC_LSE_SL2_WR_ERR_CLR — Enable Clear for level_vpac_out_{i}_en_msc_lse_sl2_wr_err (access RW1C)
  [2] ENABLE_LEVEL_VPAC_OUT_{i}_EN_MSC_LSE_SL2_RD_ERR_CLR — Enable Clear for level_vpac_out_{i}_en_msc_lse_sl2_rd_err (access RW1C)
  [1] ENABLE_LEVEL_VPAC_OUT_{i}_EN_MSC_LSE_FR_DONE_EVT_1_CLR — Enable Clear for level_vpac_out_{i}_en_msc_lse_fr_done_evt_1 (access RW1C)
  [0] ENABLE_LEVEL_VPAC_OUT_{i}_EN_MSC_LSE_FR_DONE_EVT_0_CLR — Enable Clear for level_vpac_out_{i}_en_msc_lse_fr_done_evt_0 (access RW1C)
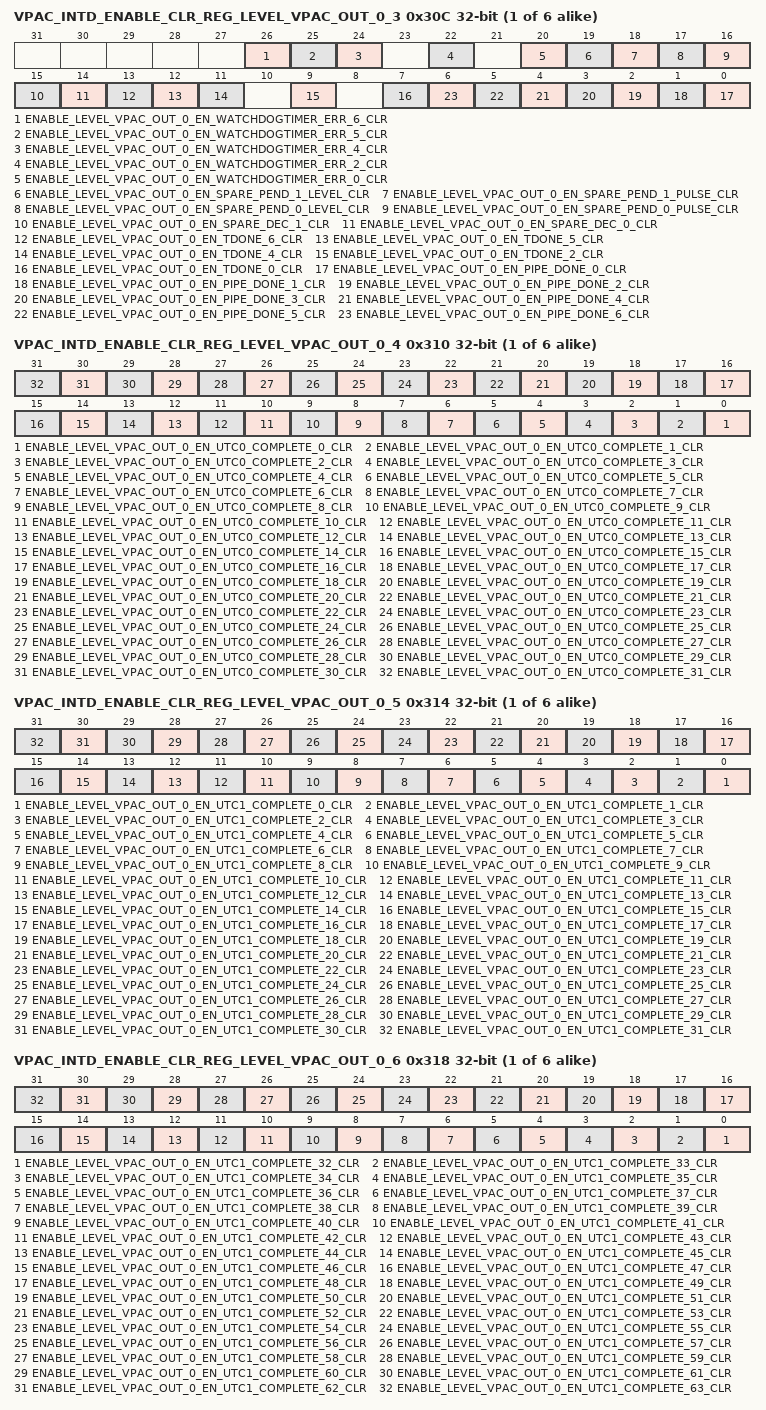
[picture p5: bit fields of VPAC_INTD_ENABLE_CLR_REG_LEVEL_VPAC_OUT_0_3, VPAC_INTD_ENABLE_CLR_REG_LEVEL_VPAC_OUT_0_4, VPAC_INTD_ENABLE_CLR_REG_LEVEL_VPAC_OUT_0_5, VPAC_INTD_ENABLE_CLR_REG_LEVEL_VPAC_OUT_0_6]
{0x30C+0x20*i} VPAC_INTD_ENABLE_CLR_REG_LEVEL_VPAC_OUT_{i}_3 (i=0..5) — Enable Clear Register {8i+3}
  [26] ENABLE_LEVEL_VPAC_OUT_{i}_EN_WATCHDOGTIMER_ERR_6_CLR — Enable Clear for level_vpac_out_{i}_en_watchdogtimer_err_6 (access RW1C)
  [25] ENABLE_LEVEL_VPAC_OUT_{i}_EN_WATCHDOGTIMER_ERR_5_CLR — Enable Clear for level_vpac_out_{i}_en_watchdogtimer_err_5 (access RW1C)
  [24] ENABLE_LEVEL_VPAC_OUT_{i}_EN_WATCHDOGTIMER_ERR_4_CLR — Enable Clear for level_vpac_out_{i}_en_watchdogtimer_err_4 (access RW1C)
  [22] ENABLE_LEVEL_VPAC_OUT_{i}_EN_WATCHDOGTIMER_ERR_2_CLR — Enable Clear for level_vpac_out_{i}_en_watchdogtimer_err_2 (access RW1C)
  [20] ENABLE_LEVEL_VPAC_OUT_{i}_EN_WATCHDOGTIMER_ERR_0_CLR — Enable Clear for level_vpac_out_{i}_en_watchdogtimer_err_0 (access RW1C)
  [19] ENABLE_LEVEL_VPAC_OUT_{i}_EN_SPARE_PEND_1_LEVEL_CLR — Enable Clear for level_vpac_out_{i}_en_spare_pend_1_level (access RW1C)
  [18] ENABLE_LEVEL_VPAC_OUT_{i}_EN_SPARE_PEND_1_PULSE_CLR — Enable Clear for level_vpac_out_{i}_en_spare_pend_1_pulse (access RW1C)
  [17] ENABLE_LEVEL_VPAC_OUT_{i}_EN_SPARE_PEND_0_LEVEL_CLR — Enable Clear for level_vpac_out_{i}_en_spare_pend_0_level (access RW1C)
  [16] ENABLE_LEVEL_VPAC_OUT_{i}_EN_SPARE_PEND_0_PULSE_CLR — Enable Clear for level_vpac_out_{i}_en_spare_pend_0_pulse (access RW1C)
  [15] ENABLE_LEVEL_VPAC_OUT_{i}_EN_SPARE_DEC_1_CLR — Enable Clear for level_vpac_out_{i}_en_spare_dec_1 (access RW1C)
  [14] ENABLE_LEVEL_VPAC_OUT_{i}_EN_SPARE_DEC_0_CLR — Enable Clear for level_vpac_out_{i}_en_spare_dec_0 (access RW1C)
  [13] ENABLE_LEVEL_VPAC_OUT_{i}_EN_TDONE_6_CLR — Enable Clear for level_vpac_out_{i}_en_tdone_6 (access RW1C)
  [12] ENABLE_LEVEL_VPAC_OUT_{i}_EN_TDONE_5_CLR — Enable Clear for level_vpac_out_{i}_en_tdone_5 (access RW1C)
  [11] ENABLE_LEVEL_VPAC_OUT_{i}_EN_TDONE_4_CLR — Enable Clear for level_vpac_out_{i}_en_tdone_4 (access RW1C)
  [9] ENABLE_LEVEL_VPAC_OUT_{i}_EN_TDONE_2_CLR — Enable Clear for level_vpac_out_{i}_en_tdone_2 (access RW1C)
  [7] ENABLE_LEVEL_VPAC_OUT_{i}_EN_TDONE_0_CLR — Enable Clear for level_vpac_out_{i}_en_tdone_0 (access RW1C)
  [n] ENABLE_LEVEL_VPAC_OUT_{i}_EN_PIPE_DONE_{n}_CLR (n=0..6) — Enable Clear for level_vpac_out_{i}_en_pipe_done_{n} (access RW1C)
{0x310+0x20*i} VPAC_INTD_ENABLE_CLR_REG_LEVEL_VPAC_OUT_{i}_4 (i=0..5) — Enable Clear Register {8i+4}
  [n] ENABLE_LEVEL_VPAC_OUT_{i}_EN_UTC0_COMPLETE_{n}_CLR (n=0..31) — Enable Clear for level_vpac_out_{i}_en_utc0_complete_{n} (access RW1C)
{0x314+0x20*i} VPAC_INTD_ENABLE_CLR_REG_LEVEL_VPAC_OUT_{i}_5 (i=0..5) — Enable Clear Register {8i+5}
  [n] ENABLE_LEVEL_VPAC_OUT_{i}_EN_UTC1_COMPLETE_{n}_CLR (n=0..31) — Enable Clear for level_vpac_out_{i}_en_utc1_complete_{n} (access RW1C)
{0x318+0x20*i} VPAC_INTD_ENABLE_CLR_REG_LEVEL_VPAC_OUT_{i}_6 (i=0..5) — Enable Clear Register {8i+6}
  [n-32] ENABLE_LEVEL_VPAC_OUT_{i}_EN_UTC1_COMPLETE_{n}_CLR (n=32..63) — Enable Clear for level_vpac_out_{i}_en_utc1_complete_{n} (access RW1C)
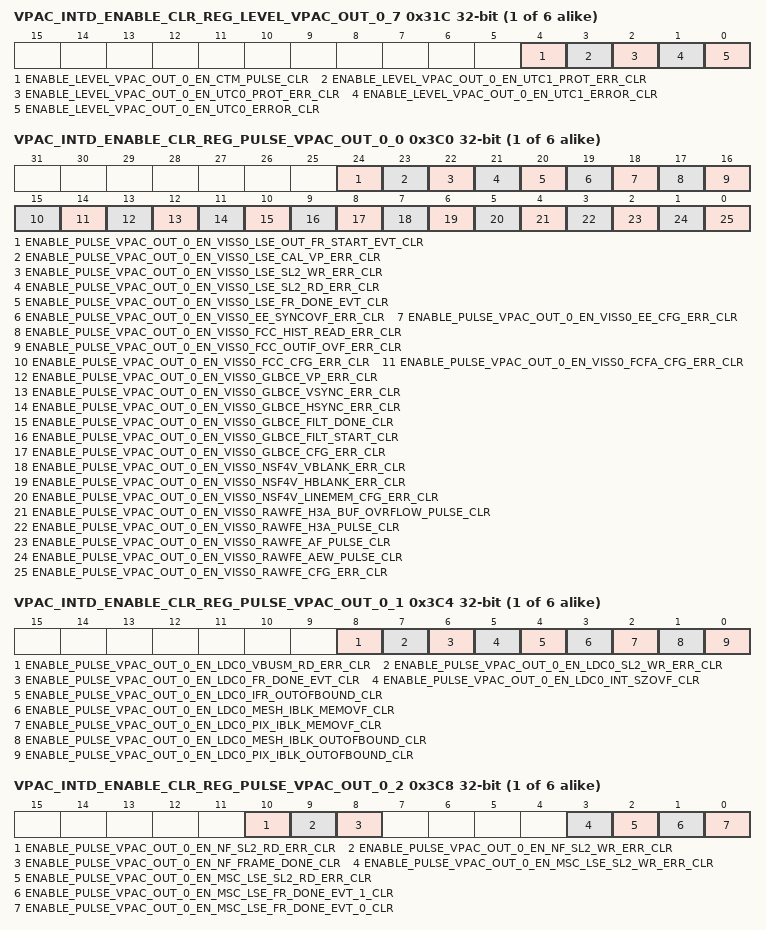
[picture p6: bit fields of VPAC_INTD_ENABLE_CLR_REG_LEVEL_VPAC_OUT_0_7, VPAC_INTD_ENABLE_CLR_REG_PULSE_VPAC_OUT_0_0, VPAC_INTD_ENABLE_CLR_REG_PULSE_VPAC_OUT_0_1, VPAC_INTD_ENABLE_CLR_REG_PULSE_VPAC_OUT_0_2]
{0x31C+0x20*i} VPAC_INTD_ENABLE_CLR_REG_LEVEL_VPAC_OUT_{i}_7 (i=0..5) — Enable Clear Register {8i+7}
  [4] ENABLE_LEVEL_VPAC_OUT_{i}_EN_CTM_PULSE_CLR — Enable Clear for level_vpac_out_{i}_en_ctm_pulse (access RW1C)
  [3] ENABLE_LEVEL_VPAC_OUT_{i}_EN_UTC1_PROT_ERR_CLR — Enable Clear for level_vpac_out_{i}_en_utc1_prot_err (access RW1C)
  [2] ENABLE_LEVEL_VPAC_OUT_{i}_EN_UTC0_PROT_ERR_CLR — Enable Clear for level_vpac_out_{i}_en_utc0_prot_err (access RW1C)
  [1] ENABLE_LEVEL_VPAC_OUT_{i}_EN_UTC1_ERROR_CLR — Enable Clear for level_vpac_out_{i}_en_utc1_error (access RW1C)
  [0] ENABLE_LEVEL_VPAC_OUT_{i}_EN_UTC0_ERROR_CLR — Enable Clear for level_vpac_out_{i}_en_utc0_error (access RW1C)
{0x3C0+0x20*i} VPAC_INTD_ENABLE_CLR_REG_PULSE_VPAC_OUT_{i}_0 (i=0..5) — Enable Clear Register {8i+48}
  [24] ENABLE_PULSE_VPAC_OUT_{i}_EN_VISS0_LSE_OUT_FR_START_EVT_CLR — Enable Clear for pulse_vpac_out_{i}_en_viss0_lse_out_fr_start_evt (access RW1C)
  [23] ENABLE_PULSE_VPAC_OUT_{i}_EN_VISS0_LSE_CAL_VP_ERR_CLR — Enable Clear for pulse_vpac_out_{i}_en_viss0_lse_cal_vp_err (access RW1C)
  [22] ENABLE_PULSE_VPAC_OUT_{i}_EN_VISS0_LSE_SL2_WR_ERR_CLR — Enable Clear for pulse_vpac_out_{i}_en_viss0_lse_sl2_wr_err (access RW1C)
  [21] ENABLE_PULSE_VPAC_OUT_{i}_EN_VISS0_LSE_SL2_RD_ERR_CLR — Enable Clear for pulse_vpac_out_{i}_en_viss0_lse_sl2_rd_err (access RW1C)
  [20] ENABLE_PULSE_VPAC_OUT_{i}_EN_VISS0_LSE_FR_DONE_EVT_CLR — Enable Clear for pulse_vpac_out_{i}_en_viss0_lse_fr_done_evt (access RW1C)
  [19] ENABLE_PULSE_VPAC_OUT_{i}_EN_VISS0_EE_SYNCOVF_ERR_CLR — Enable Clear for pulse_vpac_out_{i}_en_viss0_ee_syncovf_err (access RW1C)
  [18] ENABLE_PULSE_VPAC_OUT_{i}_EN_VISS0_EE_CFG_ERR_CLR — Enable Clear for pulse_vpac_out_{i}_en_viss0_ee_cfg_err (access RW1C)
  [17] ENABLE_PULSE_VPAC_OUT_{i}_EN_VISS0_FCC_HIST_READ_ERR_CLR — Enable Clear for pulse_vpac_out_{i}_en_viss0_fcc_hist_read_err (access RW1C)
  [16] ENABLE_PULSE_VPAC_OUT_{i}_EN_VISS0_FCC_OUTIF_OVF_ERR_CLR — Enable Clear for pulse_vpac_out_{i}_en_viss0_fcc_outif_ovf_err (access RW1C)
  [15] ENABLE_PULSE_VPAC_OUT_{i}_EN_VISS0_FCC_CFG_ERR_CLR — Enable Clear for pulse_vpac_out_{i}_en_viss0_fcc_cfg_err (access RW1C)
  [14] ENABLE_PULSE_VPAC_OUT_{i}_EN_VISS0_FCFA_CFG_ERR_CLR — Enable Clear for pulse_vpac_out_{i}_en_viss0_fcfa_cfg_err (access RW1C)
  [13] ENABLE_PULSE_VPAC_OUT_{i}_EN_VISS0_GLBCE_VP_ERR_CLR — Enable Clear for pulse_vpac_out_{i}_en_viss0_glbce_vp_err (access RW1C)
  [12] ENABLE_PULSE_VPAC_OUT_{i}_EN_VISS0_GLBCE_VSYNC_ERR_CLR — Enable Clear for pulse_vpac_out_{i}_en_viss0_glbce_vsync_err (access RW1C)
  [11] ENABLE_PULSE_VPAC_OUT_{i}_EN_VISS0_GLBCE_HSYNC_ERR_CLR — Enable Clear for pulse_vpac_out_{i}_en_viss0_glbce_hsync_err (access RW1C)
  [10] ENABLE_PULSE_VPAC_OUT_{i}_EN_VISS0_GLBCE_FILT_DONE_CLR — Enable Clear for pulse_vpac_out_{i}_en_viss0_glbce_filt_done (access RW1C)
  [9] ENABLE_PULSE_VPAC_OUT_{i}_EN_VISS0_GLBCE_FILT_START_CLR — Enable Clear for pulse_vpac_out_{i}_en_viss0_glbce_filt_start (access RW1C)
  [8] ENABLE_PULSE_VPAC_OUT_{i}_EN_VISS0_GLBCE_CFG_ERR_CLR — Enable Clear for pulse_vpac_out_{i}_en_viss0_glbce_cfg_err (access RW1C)
  [7] ENABLE_PULSE_VPAC_OUT_{i}_EN_VISS0_NSF4V_VBLANK_ERR_CLR — Enable Clear for pulse_vpac_out_{i}_en_viss0_nsf4v_vblank_err (access RW1C)
  [6] ENABLE_PULSE_VPAC_OUT_{i}_EN_VISS0_NSF4V_HBLANK_ERR_CLR — Enable Clear for pulse_vpac_out_{i}_en_viss0_nsf4v_hblank_err (access RW1C)
  [5] ENABLE_PULSE_VPAC_OUT_{i}_EN_VISS0_NSF4V_LINEMEM_CFG_ERR_CLR — Enable Clear for pulse_vpac_out_{i}_en_viss0_nsf4v_linemem_cfg_err (access RW1C)
  [4] ENABLE_PULSE_VPAC_OUT_{i}_EN_VISS0_RAWFE_H3A_BUF_OVRFLOW_PULSE_CLR — Enable Clear for pulse_vpac_out_{i}_en_viss0_rawfe_h3a_buf_ovrflow_pulse (access RW1C)
  [3] ENABLE_PULSE_VPAC_OUT_{i}_EN_VISS0_RAWFE_H3A_PULSE_CLR — Enable Clear for pulse_vpac_out_{i}_en_viss0_rawfe_h3a_pulse (access RW1C)
  [2] ENABLE_PULSE_VPAC_OUT_{i}_EN_VISS0_RAWFE_AF_PULSE_CLR — Enable Clear for pulse_vpac_out_{i}_en_viss0_rawfe_af_pulse (access RW1C)
  [1] ENABLE_PULSE_VPAC_OUT_{i}_EN_VISS0_RAWFE_AEW_PULSE_CLR — Enable Clear for pulse_vpac_out_{i}_en_viss0_rawfe_aew_pulse (access RW1C)
  [0] ENABLE_PULSE_VPAC_OUT_{i}_EN_VISS0_RAWFE_CFG_ERR_CLR — Enable Clear for pulse_vpac_out_{i}_en_viss0_rawfe_cfg_err (access RW1C)
{0x3C4+0x20*i} VPAC_INTD_ENABLE_CLR_REG_PULSE_VPAC_OUT_{i}_1 (i=0..5) — Enable Clear Register {8i+49}
  [8] ENABLE_PULSE_VPAC_OUT_{i}_EN_LDC0_VBUSM_RD_ERR_CLR — Enable Clear for pulse_vpac_out_{i}_en_ldc0_vbusm_rd_err (access RW1C)
  [7] ENABLE_PULSE_VPAC_OUT_{i}_EN_LDC0_SL2_WR_ERR_CLR — Enable Clear for pulse_vpac_out_{i}_en_ldc0_sl2_wr_err (access RW1C)
  [6] ENABLE_PULSE_VPAC_OUT_{i}_EN_LDC0_FR_DONE_EVT_CLR — Enable Clear for pulse_vpac_out_{i}_en_ldc0_fr_done_evt (access RW1C)
  [5] ENABLE_PULSE_VPAC_OUT_{i}_EN_LDC0_INT_SZOVF_CLR — Enable Clear for pulse_vpac_out_{i}_en_ldc0_int_szovf (access RW1C)
  [4] ENABLE_PULSE_VPAC_OUT_{i}_EN_LDC0_IFR_OUTOFBOUND_CLR — Enable Clear for pulse_vpac_out_{i}_en_ldc0_ifr_outofbound (access RW1C)
  [3] ENABLE_PULSE_VPAC_OUT_{i}_EN_LDC0_MESH_IBLK_MEMOVF_CLR — Enable Clear for pulse_vpac_out_{i}_en_ldc0_mesh_iblk_memovf (access RW1C)
  [2] ENABLE_PULSE_VPAC_OUT_{i}_EN_LDC0_PIX_IBLK_MEMOVF_CLR — Enable Clear for pulse_vpac_out_{i}_en_ldc0_pix_iblk_memovf (access RW1C)
  [1] ENABLE_PULSE_VPAC_OUT_{i}_EN_LDC0_MESH_IBLK_OUTOFBOUND_CLR — Enable Clear for pulse_vpac_out_{i}_en_ldc0_mesh_iblk_outofbound (access RW1C)
  [0] ENABLE_PULSE_VPAC_OUT_{i}_EN_LDC0_PIX_IBLK_OUTOFBOUND_CLR — Enable Clear for pulse_vpac_out_{i}_en_ldc0_pix_iblk_outofbound (access RW1C)
{0x3C8+0x20*i} VPAC_INTD_ENABLE_CLR_REG_PULSE_VPAC_OUT_{i}_2 (i=0..5) — Enable Clear Register {8i+50}
  [10] ENABLE_PULSE_VPAC_OUT_{i}_EN_NF_SL2_RD_ERR_CLR — Enable Clear for pulse_vpac_out_{i}_en_nf_sl2_rd_err (access RW1C)
  [9] ENABLE_PULSE_VPAC_OUT_{i}_EN_NF_SL2_WR_ERR_CLR — Enable Clear for pulse_vpac_out_{i}_en_nf_sl2_wr_err (access RW1C)
  [8] ENABLE_PULSE_VPAC_OUT_{i}_EN_NF_FRAME_DONE_CLR — Enable Clear for pulse_vpac_out_{i}_en_nf_frame_done (access RW1C)
  [3] ENABLE_PULSE_VPAC_OUT_{i}_EN_MSC_LSE_SL2_WR_ERR_CLR — Enable Clear for pulse_vpac_out_{i}_en_msc_lse_sl2_wr_err (access RW1C)
  [2] ENABLE_PULSE_VPAC_OUT_{i}_EN_MSC_LSE_SL2_RD_ERR_CLR — Enable Clear for pulse_vpac_out_{i}_en_msc_lse_sl2_rd_err (access RW1C)
  [1] ENABLE_PULSE_VPAC_OUT_{i}_EN_MSC_LSE_FR_DONE_EVT_1_CLR — Enable Clear for pulse_vpac_out_{i}_en_msc_lse_fr_done_evt_1 (access RW1C)
  [0] ENABLE_PULSE_VPAC_OUT_{i}_EN_MSC_LSE_FR_DONE_EVT_0_CLR — Enable Clear for pulse_vpac_out_{i}_en_msc_lse_fr_done_evt_0 (access RW1C)
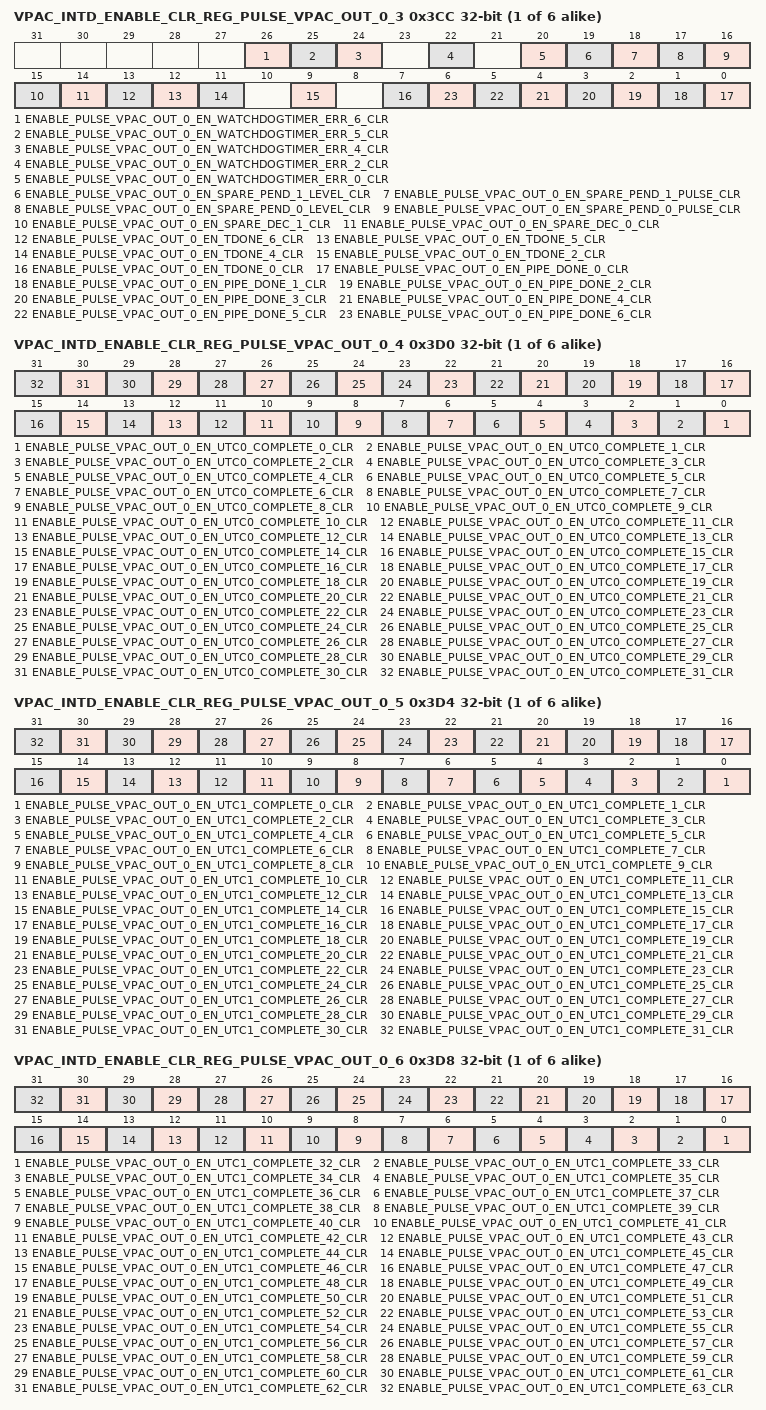
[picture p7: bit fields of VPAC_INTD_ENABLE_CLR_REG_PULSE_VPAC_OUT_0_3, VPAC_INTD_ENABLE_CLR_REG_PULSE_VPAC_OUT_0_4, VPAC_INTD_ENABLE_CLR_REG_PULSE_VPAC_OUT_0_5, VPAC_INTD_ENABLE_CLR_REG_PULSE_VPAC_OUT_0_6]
{0x3CC+0x20*i} VPAC_INTD_ENABLE_CLR_REG_PULSE_VPAC_OUT_{i}_3 (i=0..5) — Enable Clear Register {8i+51}
  [26] ENABLE_PULSE_VPAC_OUT_{i}_EN_WATCHDOGTIMER_ERR_6_CLR — Enable Clear for pulse_vpac_out_{i}_en_watchdogtimer_err_6 (access RW1C)
  [25] ENABLE_PULSE_VPAC_OUT_{i}_EN_WATCHDOGTIMER_ERR_5_CLR — Enable Clear for pulse_vpac_out_{i}_en_watchdogtimer_err_5 (access RW1C)
  [24] ENABLE_PULSE_VPAC_OUT_{i}_EN_WATCHDOGTIMER_ERR_4_CLR — Enable Clear for pulse_vpac_out_{i}_en_watchdogtimer_err_4 (access RW1C)
  [22] ENABLE_PULSE_VPAC_OUT_{i}_EN_WATCHDOGTIMER_ERR_2_CLR — Enable Clear for pulse_vpac_out_{i}_en_watchdogtimer_err_2 (access RW1C)
  [20] ENABLE_PULSE_VPAC_OUT_{i}_EN_WATCHDOGTIMER_ERR_0_CLR — Enable Clear for pulse_vpac_out_{i}_en_watchdogtimer_err_0 (access RW1C)
  [19] ENABLE_PULSE_VPAC_OUT_{i}_EN_SPARE_PEND_1_LEVEL_CLR — Enable Clear for pulse_vpac_out_{i}_en_spare_pend_1_level (access RW1C)
  [18] ENABLE_PULSE_VPAC_OUT_{i}_EN_SPARE_PEND_1_PULSE_CLR — Enable Clear for pulse_vpac_out_{i}_en_spare_pend_1_pulse (access RW1C)
  [17] ENABLE_PULSE_VPAC_OUT_{i}_EN_SPARE_PEND_0_LEVEL_CLR — Enable Clear for pulse_vpac_out_{i}_en_spare_pend_0_level (access RW1C)
  [16] ENABLE_PULSE_VPAC_OUT_{i}_EN_SPARE_PEND_0_PULSE_CLR — Enable Clear for pulse_vpac_out_{i}_en_spare_pend_0_pulse (access RW1C)
  [15] ENABLE_PULSE_VPAC_OUT_{i}_EN_SPARE_DEC_1_CLR — Enable Clear for pulse_vpac_out_{i}_en_spare_dec_1 (access RW1C)
  [14] ENABLE_PULSE_VPAC_OUT_{i}_EN_SPARE_DEC_0_CLR — Enable Clear for pulse_vpac_out_{i}_en_spare_dec_0 (access RW1C)
  [13] ENABLE_PULSE_VPAC_OUT_{i}_EN_TDONE_6_CLR — Enable Clear for pulse_vpac_out_{i}_en_tdone_6 (access RW1C)
  [12] ENABLE_PULSE_VPAC_OUT_{i}_EN_TDONE_5_CLR — Enable Clear for pulse_vpac_out_{i}_en_tdone_5 (access RW1C)
  [11] ENABLE_PULSE_VPAC_OUT_{i}_EN_TDONE_4_CLR — Enable Clear for pulse_vpac_out_{i}_en_tdone_4 (access RW1C)
  [9] ENABLE_PULSE_VPAC_OUT_{i}_EN_TDONE_2_CLR — Enable Clear for pulse_vpac_out_{i}_en_tdone_2 (access RW1C)
  [7] ENABLE_PULSE_VPAC_OUT_{i}_EN_TDONE_0_CLR — Enable Clear for pulse_vpac_out_{i}_en_tdone_0 (access RW1C)
  [n] ENABLE_PULSE_VPAC_OUT_{i}_EN_PIPE_DONE_{n}_CLR (n=0..6) — Enable Clear for pulse_vpac_out_{i}_en_pipe_done_{n} (access RW1C)
{0x3D0+0x20*i} VPAC_INTD_ENABLE_CLR_REG_PULSE_VPAC_OUT_{i}_4 (i=0..5) — Enable Clear Register {8i+52}
  [n] ENABLE_PULSE_VPAC_OUT_{i}_EN_UTC0_COMPLETE_{n}_CLR (n=0..31) — Enable Clear for pulse_vpac_out_{i}_en_utc0_complete_{n} (access RW1C)
{0x3D4+0x20*i} VPAC_INTD_ENABLE_CLR_REG_PULSE_VPAC_OUT_{i}_5 (i=0..5) — Enable Clear Register {8i+53}
  [n] ENABLE_PULSE_VPAC_OUT_{i}_EN_UTC1_COMPLETE_{n}_CLR (n=0..31) — Enable Clear for pulse_vpac_out_{i}_en_utc1_complete_{n} (access RW1C)
{0x3D8+0x20*i} VPAC_INTD_ENABLE_CLR_REG_PULSE_VPAC_OUT_{i}_6 (i=0..5) — Enable Clear Register {8i+54}
  [n-32] ENABLE_PULSE_VPAC_OUT_{i}_EN_UTC1_COMPLETE_{n}_CLR (n=32..63) — Enable Clear for pulse_vpac_out_{i}_en_utc1_complete_{n} (access RW1C)
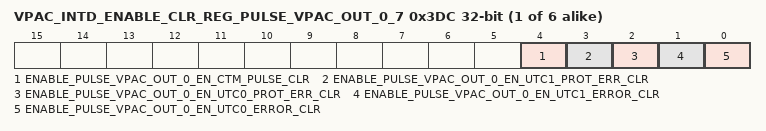
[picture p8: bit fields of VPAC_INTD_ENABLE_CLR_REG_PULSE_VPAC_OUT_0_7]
{0x3DC+0x20*i} VPAC_INTD_ENABLE_CLR_REG_PULSE_VPAC_OUT_{i}_7 (i=0..5) — Enable Clear Register {8i+55}
  [4] ENABLE_PULSE_VPAC_OUT_{i}_EN_CTM_PULSE_CLR — Enable Clear for pulse_vpac_out_{i}_en_ctm_pulse (access RW1C)
  [3] ENABLE_PULSE_VPAC_OUT_{i}_EN_UTC1_PROT_ERR_CLR — Enable Clear for pulse_vpac_out_{i}_en_utc1_prot_err (access RW1C)
  [2] ENABLE_PULSE_VPAC_OUT_{i}_EN_UTC0_PROT_ERR_CLR — Enable Clear for pulse_vpac_out_{i}_en_utc0_prot_err (access RW1C)
  [1] ENABLE_PULSE_VPAC_OUT_{i}_EN_UTC1_ERROR_CLR — Enable Clear for pulse_vpac_out_{i}_en_utc1_error (access RW1C)
  [0] ENABLE_PULSE_VPAC_OUT_{i}_EN_UTC0_ERROR_CLR — Enable Clear for pulse_vpac_out_{i}_en_utc0_error (access RW1C)
